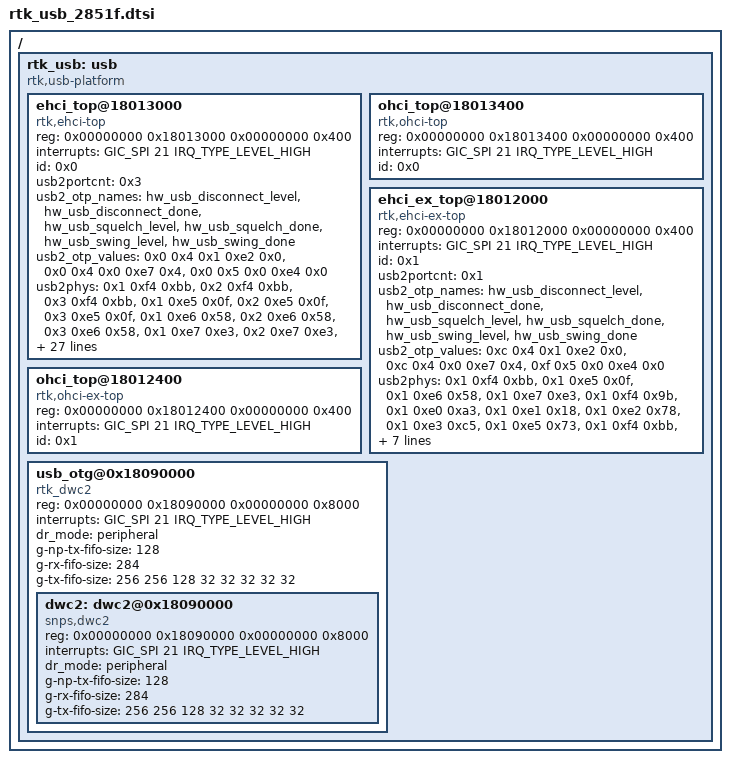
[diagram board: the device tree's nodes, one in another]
/*
 * RTK TV usb host driver device tree in the 64 bits version;
 * including the base address, parameters of phy etc.
 *
 */

/ {
	#address-cells = <1>;
	#size-cells = <1>;
	rtk_usb: usb {
		compatible = "rtk,usb-platform";
		#address-cells = <2>;
		#size-cells = <2>;
	       ranges;

		ehci_top@18013000 {
			compatible = "rtk,ehci-top";
			reg = <0x00000000 0x18013000 0x00000000 0x400>;
            		interrupts = <GIC_SPI 21 IRQ_TYPE_LEVEL_HIGH>;
            		id = <0x0>;
            		usb2portcnt = <0x3>;
            		usb2_otp_names = "hw_usb_disconnect_level", "hw_usb_disconnect_done",
			                             "hw_usb_squelch_level", "hw_usb_squelch_done",
			                             "hw_usb_swing_level", "hw_usb_swing_done";
			                             
			usb2_otp_values = <0x0 0x4 0x1 0xe2 0x0>,/* otp_offset/bitsnum/page/reg/bits_offset */
							<0x0 0x4 0x0 0xe7 0x4>,
							<0x0 0x5 0x0 0xe4 0x0>;
			usb2phys = <0x1 0xf4 0xbb>,
					    <0x2 0xf4 0xbb>,
					    <0x3 0xf4 0xbb>,
					    <0x1 0xe5 0x0f>,
					    <0x2 0xe5 0x0f>, 
					    <0x3 0xe5 0x0f>,
					    <0x1 0xe6 0x58>,
					    <0x2 0xe6 0x58>,
					    <0x3 0xe6 0x58>,
					    <0x1 0xe7 0xe3>,
					    <0x2 0xe7 0xe3>,
					    <0x3 0xe7 0xe3>,
					    <0x1 0xf4 0x9b>,
					    <0x2 0xf4 0x9b>,
					    <0x3 0xf4 0x9b>,
					    <0x1 0xe0 0xa3>,
					    <0x2 0xe0 0xa3>,
					    <0x3 0xe0 0xa3>,
					    <0x1 0xe1 0x18>,
					    <0x2 0xe1 0x18>,
					    <0x3 0xe1 0x18>,
					    <0x1 0xe2 0x78>,
					    <0x2 0xe2 0x78>,
					    <0x3 0xe2 0x78>,
					    <0x1 0xe3 0xc5>,
					    <0x2 0xe3 0xc5>,
					    <0x3 0xe3 0xc5>,
					    <0x1 0xe5 0x73>,
					    <0x2 0xe5 0x73>,
					    <0x3 0xe5 0x73>,
					    <0x1 0xf4 0xbb>,
					    <0x2 0xf4 0xbb>,
					    <0x3 0xf4 0xbb>,
					    <0x1 0xe1 0x1f>,
					    <0x2 0xe1 0x1f>,
					    <0x3 0xe1 0x1f>,
					    <0x1 0xf4 0xdb>,
					    <0x2 0xf4 0xdb>,
					    <0x3 0xf4 0xdb>,
					    <0x1 0xe7 0x55>,
					    <0x2 0xe7 0x55>,
					    <0x3 0xe7 0x55>,
					    <0x1 0xf4 0xbb>,
					    <0x2 0xf4 0xbb>,
					    <0x3 0xf4 0xbb>,
					    <0x1 0xe2 0x07>, 
					    <0x2 0xe2 0x07>,
					    <0x3 0xe2 0x07>,  
					    <0x1 0xf4 0x9b>,
					    <0x2 0xf4 0x9b>,
					    <0x3 0xf4 0x9b>,
					    <0x1 0xe7 0x71>,
					    <0x2 0xe7 0x71>,
					    <0x3 0xe7 0x71>, 
					    <0x1 0xf4 0xbb>,
					    <0x2 0xf4 0xbb>,
					    <0x3 0xf4 0xbb>,
					    <0x1 0xe0 0x21>,
					    <0x1 0xe0 0x25>,
					    <0x2 0xe0 0x21>,
					    <0x2 0xe0 0x25>,
					    <0x3 0xe0 0x21>, 
					    <0x3 0xe0 0x25>, 
					    <0x1 0xe2 0x08>,
					    <0x2 0xe2 0x08>,
					    <0x3 0xe2 0x07>, 	
					    <0x1 0xf4 0x9b>,
					    <0x2 0xf4 0x9b>,
					    <0x3 0xf4 0x9b>,
					    <0x1 0xe7 0x91>,
					    <0x2 0xe7 0x91>,
					    <0x3 0xe7 0x91>, 		
					    <0x1 0xe4 0x8d>,
					    <0x2 0xe4 0x8e>,
					    <0x3 0xe4 0x92>, 		
					    <0x1 0xe6 0x02>,
					    <0x2 0xe6 0x02>,
					    <0x3 0xe6 0x02>,     
					    <0x1 0xf5 0x95>,
					    <0x2 0xf5 0x95>,
					    <0x3 0xf5 0x95>,    
					    <0x1 0xf7 0xba>,
					    <0x2 0xf7 0xba>,
					    <0x3 0xf7 0xba>,
					    <0x1 0xf4 0xbb>,
					    <0x2 0xf4 0xbb>,
					    <0x3 0xf4 0xbb>,
					    <0x1 0xf4 0x9b>,
					    <0x2 0xf4 0x9b>,
					    <0x3 0xf4 0x9b>;
		};

		ohci_top@18013400 {
			compatible = "rtk,ohci-top";
			reg = <0x00000000 0x18013400 0x00000000 0x400>;
			interrupts = <GIC_SPI 21 IRQ_TYPE_LEVEL_HIGH>;
			id = <0x0>;
		};

		ehci_ex_top@18012000 {
			compatible = "rtk,ehci-ex-top";
			reg = <0x00000000 0x18012000 0x00000000 0x400>;
            		interrupts = <GIC_SPI 21 IRQ_TYPE_LEVEL_HIGH>;
            		id = <0x1>;
            		usb2portcnt = <0x1>;
            		usb2_otp_names = "hw_usb_disconnect_level", "hw_usb_disconnect_done",
			                             "hw_usb_squelch_level", "hw_usb_squelch_done",
			                             "hw_usb_swing_level", "hw_usb_swing_done";
			                             
			usb2_otp_values = <0xc 0x4 0x1 0xe2 0x0>,/* otp_offset/bitsnum/page/reg/bits_offset */
							<0xc 0x4 0x0 0xe7 0x4>,
							<0xf 0x5 0x0 0xe4 0x0>;
			usb2phys = <0x1 0xf4 0xbb>,
					    <0x1 0xe5 0x0f>,
					    <0x1 0xe6 0x58>,
					    <0x1 0xe7 0xe3>,
					    <0x1 0xf4 0x9b>,
					    <0x1 0xe0 0xa3>,
					    <0x1 0xe1 0x18>,
					    <0x1 0xe2 0x78>,
					    <0x1 0xe3 0xc5>,
					    <0x1 0xe5 0x73>,
					    <0x1 0xf4 0xbb>,
					    <0x1 0xe1 0x1f>,
					    <0x1 0xf4 0xdb>,
					    <0x1 0xe7 0x55>,
					    <0x1 0xf4 0xbb>,
					    <0x1 0xe2 0x07>, 
					    <0x1 0xf4 0x9b>,
					    <0x1 0xe7 0x71>,
					    <0x1 0xf4 0xbb>,
					    <0x1 0xe0 0x21>,
					    <0x1 0xe0 0x25>,
					    <0x1 0xe2 0x06>,
					    <0x1 0xf4 0x9b>,
					    <0x1 0xe7 0x91>,
					    <0x1 0xe4 0x8e>,
					    <0x1 0xe6 0x02>,
					    <0x1 0xf5 0x95>,
					    <0x1 0xf7 0xba>,
					    <0x1 0xf4 0xbb>,
					    <0x1 0xf4 0x9b>;
		};

		ohci_top@18012400 {
			compatible = "rtk,ohci-ex-top";
			reg = <0x00000000 0x18012400 0x00000000 0x400>;
			interrupts = <GIC_SPI 21 IRQ_TYPE_LEVEL_HIGH>;
			id = <0x1>;
		};		

		usb_otg@0x18090000 {
			compatible = "rtk_dwc2";
			reg = <0x00000000 0x18090000 0x00000000 0x8000>;
			interrupts = <GIC_SPI 21 IRQ_TYPE_LEVEL_HIGH>;
			dr_mode ="peripheral";
			g-np-tx-fifo-size = <128>;
			g-rx-fifo-size = <284>;
			g-tx-fifo-size = <256 256 128 32 32 32 32 32>;			
			/**for dwc2 otg**/
			#address-cells = <2>;
			#size-cells = <2>;
			ranges;
			dwc2: dwc2@0x18090000 {
				compatible = "snps,dwc2";
				reg = <0x00000000 0x18090000 0x00000000 0x8000>;
				interrupts = <GIC_SPI 21 IRQ_TYPE_LEVEL_HIGH>;
				dr_mode ="peripheral";
				g-np-tx-fifo-size = <128>;
				g-rx-fifo-size = <284>;
				g-tx-fifo-size = <256 256 128 32 32 32 32 32>;
			};
		};
	};

  };
